AUTOSAR XML (schema 00051)
package /CS_Composition/SWCs
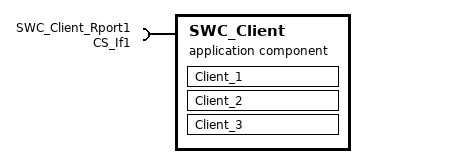
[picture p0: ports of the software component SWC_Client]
  application sw component type SWC_Client
    require port SWC_Client_Rport1: required-interface=CS_If1
      required-com-specs:
        end-to-end-call-response-timeout=50, operation=Add_ImplUint16
        end-to-end-call-response-timeout=50, operation=Sub_ImplUint16
        end-to-end-call-response-timeout=50, operation=Multiply_ImplUint16
    behavior SWC_Client_SwcInternalBehavior: port-api-option{port=SWC_Client_Rport1, error-handling=NO-TRANSFORMER-ERROR-HANDLING}
      init event InitEvent_{1..3}: start-on-event=Client_{1..3}
      runnable Client_1
        sync call CR1_SynSerCallPoint_1: return-value-provision=RETURN-VALUE-PROVIDED, timeout=50, operation=SWC_Client_Rport1.Add_ImplUint16
        async call CR1_AsynSerCallPoint_1: return-value-provision=RETURN-VALUE-PROVIDED, operation=SWC_Client_Rport1.Add_ImplUint16
      runnable Client_2
        sync call CR2_SynSerCallPoint_1: return-value-provision=RETURN-VALUE-PROVIDED, timeout=50, operation=SWC_Client_Rport1.Add_ImplUint16
        async call CR2_AsynSerCallPoint_1: return-value-provision=RETURN-VALUE-PROVIDED, operation=SWC_Client_Rport1.Add_ImplUint16
      runnable Client_3
        sync call CR3_SynSerCallPoint_1: return-value-provision=RETURN-VALUE-PROVIDED, timeout=50, operation=SWC_Client_Rport1.Multiply_ImplUint16
        async call CR3_AsynSerCallPoint_1: return-value-provision=RETURN-VALUE-PROVIDED, operation=SWC_Client_Rport1.Multiply_ImplUint16
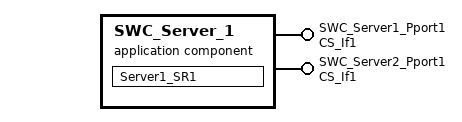
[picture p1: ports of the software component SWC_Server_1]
  application sw component type SWC_Server_1
    provide port SWC_Server1_Pport1: provided-interface=CS_If1, server-com-spec{operation=Add_ImplUint16, queue-length=20}
    provide port SWC_Server2_Pport1: provided-interface=CS_If1, server-com-spec{operation=Multiply_ImplUint16, queue-length=20}
    behavior SWC_Server1_SwcInternalBehavior
      operation invoked event OperationInvokedEvent_1: start-on-event=Server1_SR1, operation=SWC_Server1_Pport1.Add_ImplUint16
      operation invoked event OperationInvokedEvent_2: start-on-event=Server1_SR1, operation=SWC_Server1_Pport1.Add_ImplUint16
      runnable Server1_SR1: can-be-invoked-concurrently=true
  application sw component type SWC_Server_2
    behavior SWC_Server2_SwcInternalBehavior
      operation invoked event OperationInvokedEvent_3: start-on-event=Server2_SR1, operation=SWC_Server2_Pport1.Multiply_ImplUint16
      runnable Server2_SR1: can-be-invoked-concurrently=true
